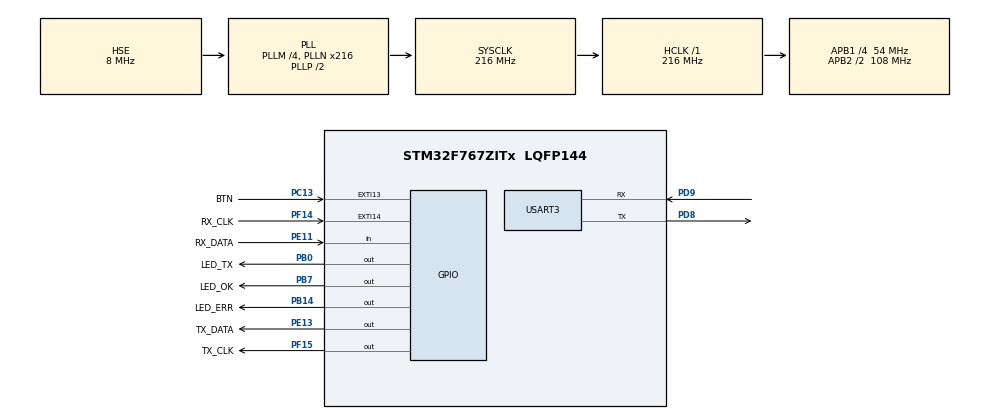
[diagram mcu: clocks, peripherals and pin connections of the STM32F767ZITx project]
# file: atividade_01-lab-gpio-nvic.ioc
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Mcu.Family=STM32F7
Mcu.Name=STM32F767ZITx
Mcu.Package=LQFP144
NVIC.EXTI15_10_IRQn=true\:0\:0\:false\:false\:true\:true\:true\:true
NVIC.PriorityGroup=NVIC_PRIORITYGROUP_4
PA13.Mode=Serial_Wire
PA13.Signal=SYS_JTMS-SWDIO
PA14.Mode=Serial_Wire
PA14.Signal=SYS_JTCK-SWCLK
PB0.GPIO_Label=LED_TX
PB0.Signal=GPIO_Output
PB14.GPIO_Label=LED_ERR
PB14.Signal=GPIO_Output
PB7.GPIO_Label=LED_OK
PB7.Signal=GPIO_Output
PC13.GPIO_Label=BTN
PC13.Signal=GPXTI13
PD8.Mode=Asynchronous
PD8.Signal=USART3_TX
PD9.Mode=Asynchronous
PD9.Signal=USART3_RX
PE11.GPIO_PuPd=GPIO_PULLDOWN
PE11.GPIO_Label=RX_DATA
PE11.Signal=GPIO_Input
PE13.GPIO_Speed=GPIO_SPEED_FREQ_VERY_HIGH
PE13.GPIO_Label=TX_DATA
PE13.Signal=GPIO_Output
PF14.GPIO_PuPd=GPIO_PULLDOWN
PF14.GPIO_Label=RX_CLK
PF14.Signal=GPXTI14
PF15.GPIO_Speed=GPIO_SPEED_FREQ_VERY_HIGH
PF15.GPIO_Label=TX_CLK
PF15.Signal=GPIO_Output
PH0/OSC_IN.Mode=HSE-External-Clock-Source
PH0/OSC_IN.Signal=RCC_OSC_IN
PH1/OSC_OUT.Mode=HSE-External-Clock-Source
PH1/OSC_OUT.Signal=RCC_OSC_OUT
ProjectManager.HeapSize=0x200
ProjectManager.StackSize=0x400
ProjectManager.TargetToolchain=STM32CubeIDE
RCC.AHBFreq_Value=216000000
RCC.APB1CLKDivider=RCC_HCLK_DIV4
RCC.APB1Freq_Value=54000000
RCC.APB1TimFreq_Value=108000000
RCC.APB2CLKDivider=RCC_HCLK_DIV2
RCC.APB2Freq_Value=108000000
RCC.APB2TimFreq_Value=216000000
RCC.CortexFreq_Value=216000000
RCC.HCLKFreq_Value=216000000
RCC.HSE_VALUE=8000000
RCC.HSI_VALUE=16000000
RCC.LSE_VALUE=32768
RCC.PLLM=4
RCC.PLLN=216
RCC.PLLSourceVirtual=RCC_PLLSOURCE_HSE
RCC.SYSCLKFreq_VALUE=216000000
RCC.SYSCLKSource=RCC_SYSCLKSOURCE_PLLCLK
RCC.USBFreq_Value=216000000
RCC.VCOOutputFreq_Value=432000000
USART3.VirtualMode-Asynchronous=VM_ASYNC
board=custom

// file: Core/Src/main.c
/* USER CODE BEGIN Header */
/**
  ******************************************************************************
  * @file           : main.c
  * @brief          : Main program body
  ******************************************************************************
  * @attention
  *
  * Copyright (c) 2026 STMicroelectronics.
  * All rights reserved.
  *
  * This software is licensed under terms that can be found in the LICENSE file
  * in the root directory of this software component.
  * If no LICENSE file comes with this software, it is provided AS-IS.
  *
  ******************************************************************************
  */
/* USER CODE END Header */
#include "main.h"

/* USER CODE BEGIN Includes */
#include "bsp.h"
#include "app.h"

/* USER CODE END Includes */

UART_HandleTypeDef huart3;

void SystemClock_Config(void);
static void MX_GPIO_Init(void);
static void MX_USART3_UART_Init(void);

int main(void)
{

  /* MCU Configuration--------------------------------------------------------*/

  /* Reset of all peripherals, Initializes the Flash interface and the Systick. */
  HAL_Init();

  /* Configure the system clock */
  SystemClock_Config();

  /* Initialize all configured peripherals */
  MX_GPIO_Init();
  MX_USART3_UART_Init();
  /* USER CODE BEGIN 2 */
  bsp_init(&huart3);   /* camada de hardware: LEDs, botao, pinos do link, DWT, console */
  app_init();          /* protocolo + aplicacao de teste */

  /* USER CODE END 2 */

  /* Infinite loop */
  while (1)
  {

    /* USER CODE BEGIN 3 */
    app_loop();        /* superloop bare-metal: nao bloqueia, chamado continuamente */
  }
  /* USER CODE END 3 */
}

void SystemClock_Config(void)
{
  RCC_OscInitTypeDef RCC_OscInitStruct = {0};
  RCC_ClkInitTypeDef RCC_ClkInitStruct = {0};

  /** Configure the main internal regulator output voltage
  */
  __HAL_RCC_PWR_CLK_ENABLE();
  __HAL_PWR_VOLTAGESCALING_CONFIG(PWR_REGULATOR_VOLTAGE_SCALE1);

  /** Initializes the RCC Oscillators according to the specified parameters
  * in the RCC_OscInitTypeDef structure.
  */
  RCC_OscInitStruct.OscillatorType = RCC_OSCILLATORTYPE_HSE;
  RCC_OscInitStruct.HSEState = RCC_HSE_BYPASS;
  RCC_OscInitStruct.PLL.PLLState = RCC_PLL_ON;
  RCC_OscInitStruct.PLL.PLLSource = RCC_PLLSOURCE_HSE;
  RCC_OscInitStruct.PLL.PLLM = 4;
  RCC_OscInitStruct.PLL.PLLN = 216;
  RCC_OscInitStruct.PLL.PLLP = RCC_PLLP_DIV2;
  RCC_OscInitStruct.PLL.PLLQ = 2;
  RCC_OscInitStruct.PLL.PLLR = 2;
  if (HAL_RCC_OscConfig(&RCC_OscInitStruct) != HAL_OK)
  {
    Error_Handler();
  }

  /** Activate the Over-Drive mode
  */
  if (HAL_PWREx_EnableOverDrive() != HAL_OK)
  {
    Error_Handler();
  }

  /** Initializes the CPU, AHB and APB buses clocks
  */
  RCC_ClkInitStruct.ClockType = RCC_CLOCKTYPE_HCLK|RCC_CLOCKTYPE_SYSCLK
                              |RCC_CLOCKTYPE_PCLK1|RCC_CLOCKTYPE_PCLK2;
  RCC_ClkInitStruct.SYSCLKSource = RCC_SYSCLKSOURCE_PLLCLK;
  RCC_ClkInitStruct.AHBCLKDivider = RCC_SYSCLK_DIV1;
  RCC_ClkInitStruct.APB1CLKDivider = RCC_HCLK_DIV4;
  RCC_ClkInitStruct.APB2CLKDivider = RCC_HCLK_DIV2;

  if (HAL_RCC_ClockConfig(&RCC_ClkInitStruct, FLASH_LATENCY_7) != HAL_OK)
  {
    Error_Handler();
  }
}

static void MX_USART3_UART_Init(void)
{

  huart3.Instance = USART3;
  huart3.Init.BaudRate = 115200;
  huart3.Init.WordLength = UART_WORDLENGTH_8B;
  huart3.Init.StopBits = UART_STOPBITS_1;
  huart3.Init.Parity = UART_PARITY_NONE;
  huart3.Init.Mode = UART_MODE_TX_RX;
  huart3.Init.HwFlowCtl = UART_HWCONTROL_NONE;
  huart3.Init.OverSampling = UART_OVERSAMPLING_16;
  huart3.Init.OneBitSampling = UART_ONE_BIT_SAMPLE_DISABLE;
  huart3.AdvancedInit.AdvFeatureInit = UART_ADVFEATURE_NO_INIT;
  if (HAL_UART_Init(&huart3) != HAL_OK)
  {
    Error_Handler();
  }

}

static void MX_GPIO_Init(void)
{
  GPIO_InitTypeDef GPIO_InitStruct = {0};

  /* GPIO Ports Clock Enable */
  __HAL_RCC_GPIOC_CLK_ENABLE();
  __HAL_RCC_GPIOH_CLK_ENABLE();
  __HAL_RCC_GPIOB_CLK_ENABLE();
  __HAL_RCC_GPIOF_CLK_ENABLE();
  __HAL_RCC_GPIOE_CLK_ENABLE();
  __HAL_RCC_GPIOD_CLK_ENABLE();
  __HAL_RCC_GPIOA_CLK_ENABLE();

  /*Configure GPIO pin Output Level */
  HAL_GPIO_WritePin(GPIOB, LED_TX_Pin|LED_ERR_Pin|LED_OK_Pin, GPIO_PIN_RESET);

  /*Configure GPIO pin Output Level */
  HAL_GPIO_WritePin(TX_CLK_GPIO_Port, TX_CLK_Pin, GPIO_PIN_RESET);

  /*Configure GPIO pin Output Level */
  HAL_GPIO_WritePin(TX_DATA_GPIO_Port, TX_DATA_Pin, GPIO_PIN_RESET);

  /*Configure GPIO pin : BTN_Pin */
  GPIO_InitStruct.Pin = BTN_Pin;
  GPIO_InitStruct.Mode = GPIO_MODE_IT_RISING;
  GPIO_InitStruct.Pull = GPIO_NOPULL;
  HAL_GPIO_Init(BTN_GPIO_Port, &GPIO_InitStruct);

  /*Configure GPIO pins : LED_TX_Pin LED_ERR_Pin LED_OK_Pin */
  GPIO_InitStruct.Pin = LED_TX_Pin|LED_ERR_Pin|LED_OK_Pin;
  GPIO_InitStruct.Mode = GPIO_MODE_OUTPUT_PP;
  GPIO_InitStruct.Pull = GPIO_NOPULL;
  GPIO_InitStruct.Speed = GPIO_SPEED_FREQ_LOW;
  HAL_GPIO_Init(GPIOB, &GPIO_InitStruct);

  /*Configure GPIO pin : RX_CLK_Pin */
  GPIO_InitStruct.Pin = RX_CLK_Pin;
  GPIO_InitStruct.Mode = GPIO_MODE_IT_RISING;
  GPIO_InitStruct.Pull = GPIO_PULLDOWN;
  HAL_GPIO_Init(RX_CLK_GPIO_Port, &GPIO_InitStruct);

  /*Configure GPIO pin : TX_CLK_Pin */
  GPIO_InitStruct.Pin = TX_CLK_Pin;
  GPIO_InitStruct.Mode = GPIO_MODE_OUTPUT_PP;
  GPIO_InitStruct.Pull = GPIO_NOPULL;
  GPIO_InitStruct.Speed = GPIO_SPEED_FREQ_VERY_HIGH;
  HAL_GPIO_Init(TX_CLK_GPIO_Port, &GPIO_InitStruct);

  /*Configure GPIO pin : RX_DATA_Pin */
  GPIO_InitStruct.Pin = RX_DATA_Pin;
  GPIO_InitStruct.Mode = GPIO_MODE_INPUT;
  GPIO_InitStruct.Pull = GPIO_PULLDOWN;
  HAL_GPIO_Init(RX_DATA_GPIO_Port, &GPIO_InitStruct);

  /*Configure GPIO pin : TX_DATA_Pin */
  GPIO_InitStruct.Pin = TX_DATA_Pin;
  GPIO_InitStruct.Mode = GPIO_MODE_OUTPUT_PP;
  GPIO_InitStruct.Pull = GPIO_NOPULL;
  GPIO_InitStruct.Speed = GPIO_SPEED_FREQ_VERY_HIGH;
  HAL_GPIO_Init(TX_DATA_GPIO_Port, &GPIO_InitStruct);

  /* EXTI interrupt init*/
  HAL_NVIC_SetPriority(EXTI15_10_IRQn, 0, 0);
  HAL_NVIC_EnableIRQ(EXTI15_10_IRQn);

}

void Error_Handler(void)
{
  __disable_irq();
  while (1)
  {
  }
}
